# AltaRiscv register map
File version: 1.0
Registers are 32-bit, read-write, reset 0x0 unless marked. A register's access mark holds for its fields unless they carry their own. Offsets are from the block's base; [hi:lo] are bit positions; {n}, {i} and the like mark numbered series.

## SYS — System control
Base 0x03000000
0x00 BOOT_MODE ro
  [1:0] BOOT_MODE
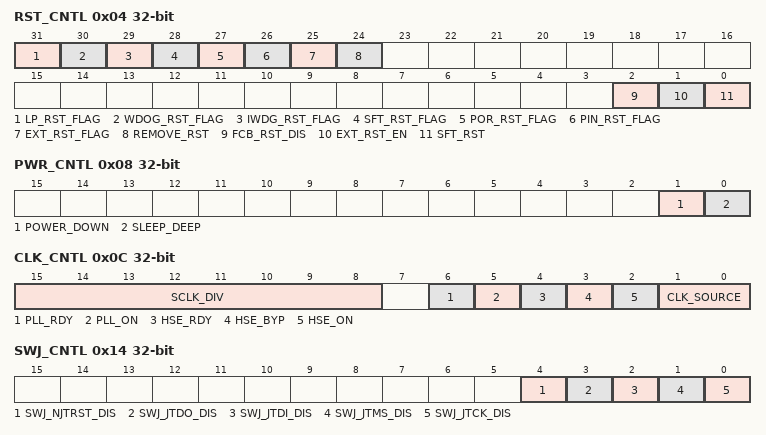
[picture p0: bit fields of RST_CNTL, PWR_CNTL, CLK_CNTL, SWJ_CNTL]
0x04 RST_CNTL access per field — Reset control register
  [31] LP_RST_FLAG ro — Low power reset flag
  [30] WDOG_RST_FLAG ro — Watch dog reset flag
  [29] IWDG_RST_FLAG ro — IWDG reset flag
  [28] SFT_RST_FLAG ro — Software reset flag
  [27] POR_RST_FLAG ro — Power on reset flag
  [26] PIN_RST_FLAG ro — Pin reset flag
  [25] EXT_RST_FLAG ro — External reset flag
  [24] REMOVE_RST wo — Remove reset flags
  [2] FCB_RST_DIS rw — FCB reset disable
  [1] EXT_RST_EN rw — External reset enable
  [0] SFT_RST rw — Software reset
0x08 PWR_CNTL — Power control register
  [1] POWER_DOWN — Standy mode enable
  [0] SLEEP_DEEP — Stop mode enable
0x0C CLK_CNTL access per field — Clock control register
  [15:8] SCLK_DIV rw — Sclk divider
  [6] PLL_RDY ro — PLL clock ready
  [5] PLL_ON rw — PLL clock enable
  [4] HSE_RDY ro — HSE clock ready
  [3] HSE_BYP rw — HSE clock bypass
  [2] HSE_ON rw — HSE clock enable
  [1:0] CLK_SOURCE rw — Clock source
    0=HSI; 1=HSE; 2=PLL; 3=External
0x10 BUS_CNTL — Bus control register
  [0] EXT_AHB_SEL — External AHB select
0x14 SWJ_CNTL — SWJ pin control register
  [4] SWJ_NJTRST_DIS — Disable NJTRST pin and use it as GPIO
  [3] SWJ_JTDO_DIS — Disable JTDO pin and use it as GPIO
  [2] SWJ_JTDI_DIS — Disable JTDI pin and use it as GPIO
  [1] SWJ_JTMS_DIS — Disable JTMS pin and use it as GPIO
  [0] SWJ_JTCK_DIS — Disable JTCK pin and use it as GPIO
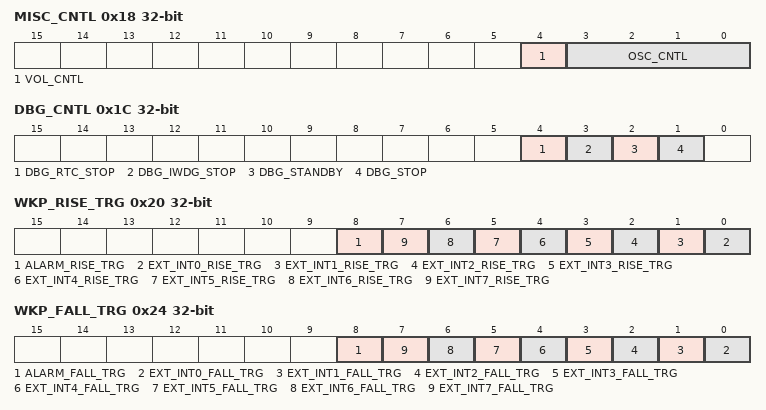
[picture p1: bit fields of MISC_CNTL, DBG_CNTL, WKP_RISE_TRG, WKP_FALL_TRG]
0x18 MISC_CNTL — Miscellaneous control register
  [4] VOL_CNTL — Voltage control
  [3:0] OSC_CNTL — Oscillator control
0x1C DBG_CNTL — Debug control register
  [4] DBG_RTC_STOP — Stop RTC during debug
  [3] DBG_IWDG_STOP — Stop IWDG during debug
  [2] DBG_STANDBY — Debug standby mode
  [1] DBG_STOP — Debug stop mode
0x20 WKP_RISE_TRG — Wake up rise triggers
  [8] ALARM_RISE_TRG — Alarm rise trigger
  [n] EXT_INT{n}_RISE_TRG (n=0..7) — External interrupt {n} rise trigger
0x24 WKP_FALL_TRG — Wake up fall triggers
  [8] ALARM_FALL_TRG — Alarm fall trigger
  [n] EXT_INT{n}_FALL_TRG (n=0..7) — External interrupt {n} fall trigger
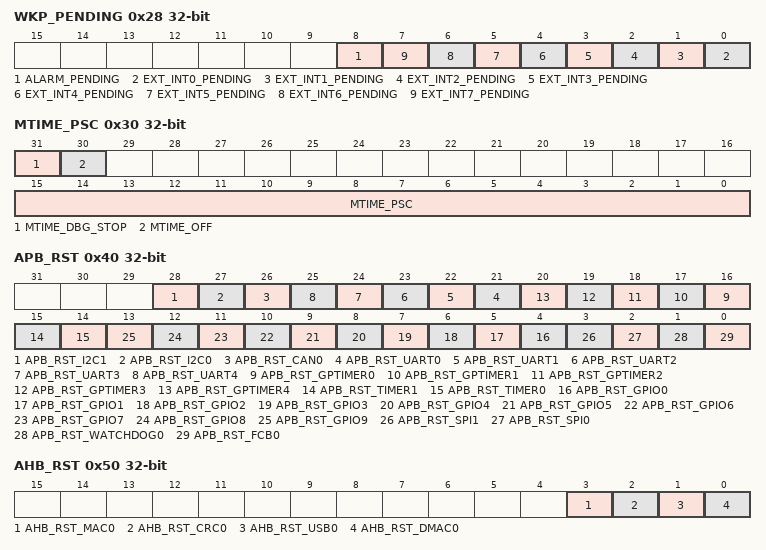
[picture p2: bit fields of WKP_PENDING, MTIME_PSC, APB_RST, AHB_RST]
0x28 WKP_PENDING — Wake up pending register
  [8] ALARM_PENDING
  [n] EXT_INT{n}_PENDING (n=0..7) — External interrupt {n} pending
0x30 MTIME_PSC — Mtime prescaler value
  [31] MTIME_DBG_STOP — Stop mtime during debug
  [30] MTIME_OFF
  [15:0] MTIME_PSC — Mtime prescaler value
0x34 MTIME_PSC_CNT ro — Mtime prescaler counter
  [15:0] MTIME_PSC_CNT
0x38 PBUS_DIV — Pbus clock divider
  [3:0] PBUS_DIV
0x40 APB_RST — APB peripheral reset
  [28] APB_RST_I2C1 — APB reset for I2C
  [27] APB_RST_I2C0 — APB reset for I2C
  [26] APB_RST_CAN0 — APB reset for CAN
  [n+21] APB_RST_UART{n} (n=0..4) — APB reset for UART
  [n+16] APB_RST_GPTIMER{n} (n=0..4) — APB reset for GPTIMER
  [15] APB_RST_TIMER1 — APB reset for TIMER
  [14] APB_RST_TIMER0 — APB reset for TIMER
  [n+4] APB_RST_GPIO{n} (n=0..9) — APB reset for GPIO
  [3] APB_RST_SPI1 — APB reset for SPI
  [2] APB_RST_SPI0 — APB reset for SPI
  [1] APB_RST_WATCHDOG0 — APB reset for WATCHDOG
  [0] APB_RST_FCB0 — APB reset for FCB
0x50 AHB_RST — AHB peripheral reset
  [3] AHB_RST_MAC0 — AHB reset for MAC
  [2] AHB_RST_CRC0 — AHB reset for CRC
  [1] AHB_RST_USB0 — AHB reset for USB
  [0] AHB_RST_DMAC0 — AHB reset for DMAC
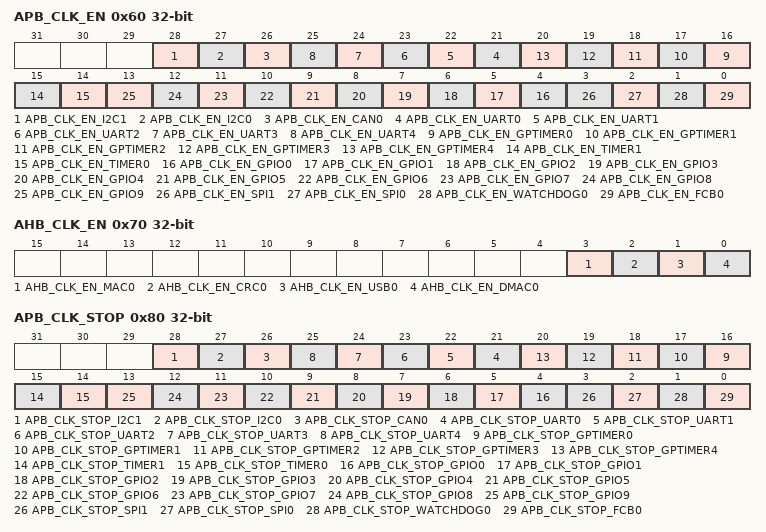
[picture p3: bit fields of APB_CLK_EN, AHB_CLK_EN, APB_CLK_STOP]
0x60 APB_CLK_EN — APB peripheral clock enable
  [28] APB_CLK_EN_I2C1 — APB clock enable for I2C
  [27] APB_CLK_EN_I2C0 — APB clock enable for I2C
  [26] APB_CLK_EN_CAN0 — APB clock enable for CAN
  [n+21] APB_CLK_EN_UART{n} (n=0..4) — APB clock enable for UART
  [n+16] APB_CLK_EN_GPTIMER{n} (n=0..4) — APB clock enable for GPTIMER
  [15] APB_CLK_EN_TIMER1 — APB clock enable for TIMER
  [14] APB_CLK_EN_TIMER0 — APB clock enable for TIMER
  [n+4] APB_CLK_EN_GPIO{n} (n=0..9) — APB clock enable for GPIO
  [3] APB_CLK_EN_SPI1 — APB clock enable for SPI
  [2] APB_CLK_EN_SPI0 — APB clock enable for SPI
  [1] APB_CLK_EN_WATCHDOG0 — APB clock enable for WATCHDOG
  [0] APB_CLK_EN_FCB0 — APB clock enable for FCB
0x70 AHB_CLK_EN — AHB peripheral clock enable
  [3] AHB_CLK_EN_MAC0 — AHB clock enable for MAC
  [2] AHB_CLK_EN_CRC0 — AHB clock enable for CRC
  [1] AHB_CLK_EN_USB0 — AHB clock enable for USB
  [0] AHB_CLK_EN_DMAC0 — AHB clock enable for DMAC
0x80 APB_CLK_STOP — APB peripheral clock stop during debug
  [28] APB_CLK_STOP_I2C1 — APB clock clock for I2C
  [27] APB_CLK_STOP_I2C0 — APB clock clock for I2C
  [26] APB_CLK_STOP_CAN0 — APB clock clock for CAN
  [n+21] APB_CLK_STOP_UART{n} (n=0..4) — APB clock clock for UART
  [n+16] APB_CLK_STOP_GPTIMER{n} (n=0..4) — APB clock clock for GPTIMER
  [15] APB_CLK_STOP_TIMER1 — APB clock clock for TIMER
  [14] APB_CLK_STOP_TIMER0 — APB clock clock for TIMER
  [n+4] APB_CLK_STOP_GPIO{n} (n=0..9) — APB clock clock for GPIO
  [3] APB_CLK_STOP_SPI1 — APB clock clock for SPI
  [2] APB_CLK_STOP_SPI0 — APB clock clock for SPI
  [1] APB_CLK_STOP_WATCHDOG0 — APB clock clock for WATCHDOG
  [0] APB_CLK_STOP_FCB0 — APB clock clock for FCB
0x100 DEVICE_ID ro — Device ID code
